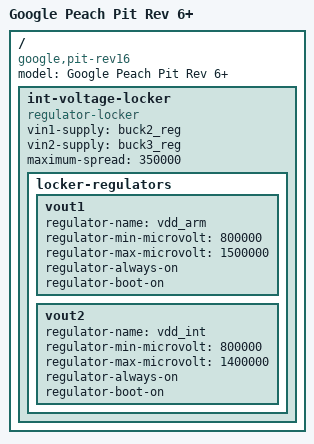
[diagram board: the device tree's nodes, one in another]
/*
 * Google Peach Pit Rev 6+ board device tree source
 *
 * Copyright (c) 2013 Google, Inc
 *
 * This program is free software; you can redistribute it and/or modify
 * it under the terms of the GNU General Public License version 2 as
 * published by the Free Software Foundation.
 */

/dts-v1/;
#include "exynos5420.dtsi"
#include "exynos542x-peach.dtsi"
#include "exynos5420-peach-pit.dtsi"
#include "cros-ec-keyboard.dtsi"

/ {
	model = "Google Peach Pit Rev 6+";

	compatible = "google,pit-rev16",
		"google,pit-rev15", "google,pit-rev14",
		"google,pit-rev13", "google,pit-rev12",
		"google,pit-rev11", "google,pit-rev10",
		"google,pit-rev9", "google,pit-rev8",
		"google,pit-rev7", "google,pit-rev6",
		"google,pit", "google,peach", "samsung,exynos5420";

	int-voltage-locker {
		compatible = "regulator-locker";
		vin1-supply = <&buck2_reg>; /* vdd_arm_real */
		vin2-supply = <&buck3_reg>; /* vdd_int_real */
		maximum-spread = <350000>;
		locker-regulators {
			vout1 {
				regulator-name = "vdd_arm";
				regulator-min-microvolt = <800000>;
				regulator-max-microvolt = <1500000>;
				regulator-always-on;
				regulator-boot-on;
			};
			vout2 {
				regulator-name = "vdd_int";
				regulator-min-microvolt = <800000>;
				regulator-max-microvolt = <1400000>;
				regulator-always-on;
				regulator-boot-on;
			};
		};
	};
};
